# SWM261 register map
File version: 1.0
SWM261 Microcontroller registers
CPU: CM0 r1p0, little endian, 2 interrupt priority bits
Registers are 32-bit, read-write, no defined reset value unless marked. A register's access mark holds for its fields unless they carry their own. Offsets are from the block's base; lines under a group give offsets from that group; [hi:lo] are bit positions; {n}, {i} and the like mark numbered series; 'fields as' and 'values as' point back to an identical list; <NAME> marks a mode.

## Memory map
0x40000000 SYS size 0x45854 — Registers group
0x40000800 DMA size 0x50 — Registers group
0x40001800 QSPI0 size 0x44 — Registers group
0x40002800 CRC size 0x10 — Registers group
0x40003000 DIV size 0x28 — Registers group
0x40003800 GPIOA size 0x80 — Registers group
0x40004000 GPIOB size 0x80
0x40004800 GPIOC size 0x80
0x40005000 MPU size 0x18 — Registers group
0x40040000 UART0 size 0x20 — Registers group
0x40040800 UART1 size 0x20
0x40041000 QEI size 0x34 — Registers group
0x40041800 SPI0 size 0x14 — Registers group
0x40042000 I2C0 size 0x38 — Registers group
0x40042800 CAN0 size 0x3C0 — Registers group
0x40043000 PWM0 size 0x80 — Registers group
0x40043080 PWM1 size 0x80
0x40043400 PWMG size 0x2C — Registers group
0x40043800 TIMR0 size 0x34 — Registers group
0x40043840 TIMR1 size 0x34
0x40043880 TIMR2 size 0x34
0x40043C00 TIMRG size 0x44 — Registers group
0x40044000 BTIMR0 size 0x34
0x40044040 BTIMR1 size 0x34
0x40044080 BTIMR2 size 0x34
0x400440C0 BTIMR3 size 0x34
0x40044400 BTIMRG size 0x44
0x40044800 ADC0 size 0x204 — Registers group
0x40044900 ADC1 size 0x204
0x40045000 FMC size 0x2C — Registers group
0x40046000 PORTA size 0x404 — Registers group
0x40046010 PORTB size 0x404
0x40046020 PORTC size 0x404
0x40046800 WDT size 0x14 — Registers group
0x40047000 USART0 size 0x60 — Registers group

## SYS — Registers group
Base 0x40000000
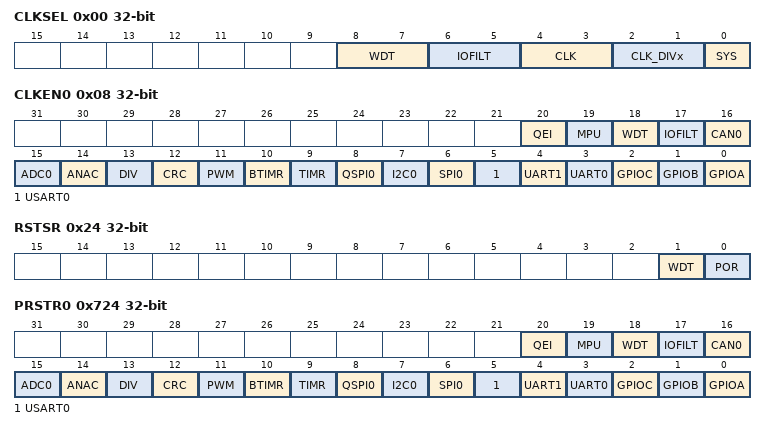
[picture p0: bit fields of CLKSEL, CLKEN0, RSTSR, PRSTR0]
0x00 CLKSEL
  [8:7] WDT, [6:5] IOFILT, [4:3] CLK, [2:1] CLK_DIVx, [0] SYS
0x04 CLKDIVx_ON
0x08 CLKEN0
  [20] QEI, [19] MPU, [18] WDT, [17] IOFILT, [16] CAN0, [15] ADC0, [14] ANAC, [13] DIV, [12] CRC, [11] PWM, [10] BTIMR, [9] TIMR, [8] QSPI0, [7] I2C0, [6] SPI0, [5] USART0, [4] UART1, [3] UART0, [2] GPIOC, [1] GPIOB, [0] GPIOA
0x10 SLEEP
  [0] SLEEP
0x24 RSTSR
  [1] WDT, [0] POR
{0x80+4i} CHIPID[{i}] (i=0..3) ro
{0x90+4i} BACKUP[{i}] (i=0..3)
0x100 PAWKEN
0x104 PBWKEN
0x108 PCWKEN
0x130 PAWKSR
0x134 PBWKSR
0x138 PCWKSR
0x400 IOFILT0
0x404 IOFILT1
0x720 PRSTEN
0x724 PRSTR0
  fields as CLKEN0
0x45800 PMUCR
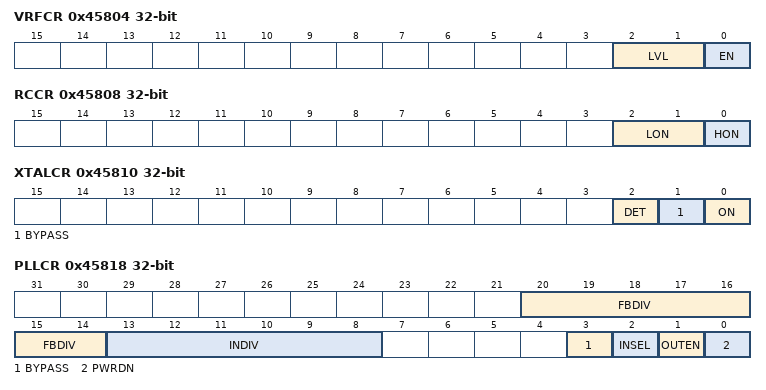
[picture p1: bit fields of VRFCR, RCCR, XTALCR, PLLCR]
0x45804 VRFCR
  [2:1] LVL, [0] EN
0x45808 RCCR
  [2:1] LON, [0] HON
0x45810 XTALCR
  [2] DET, [1] BYPASS, [0] ON
0x45814 XTALSR
  [0] STOP
0x45818 PLLCR
  [20:14] FBDIV, [13:8] INDIV, [3] BYPASS, [2] INSEL, [1] OUTEN, [0] PWRDN
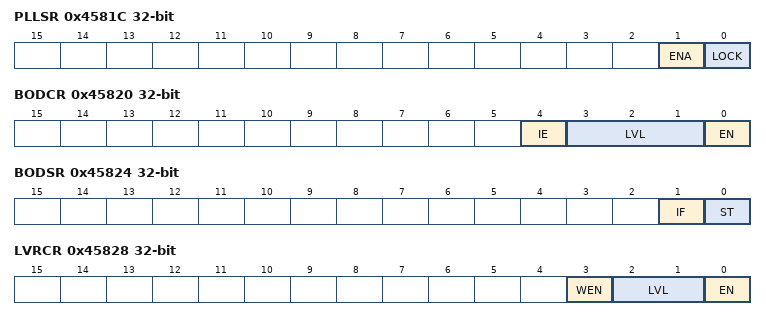
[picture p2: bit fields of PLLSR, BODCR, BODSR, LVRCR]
0x4581C PLLSR
  [1] ENA, [0] LOCK
0x45820 BODCR
  [4] IE, [3:1] LVL, [0] EN
0x45824 BODSR
  [1] IF, [0] ST
0x45828 LVRCR
  [3] WEN, [2:1] LVL, [0] EN
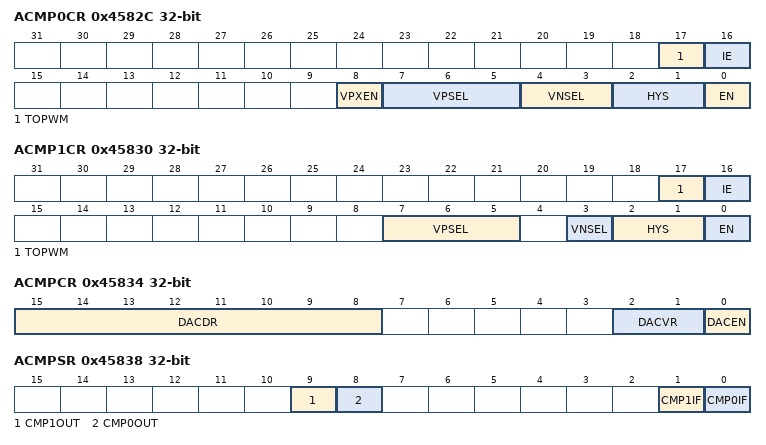
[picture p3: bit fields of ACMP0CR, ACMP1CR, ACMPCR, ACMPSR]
0x4582C ACMP0CR
  [17] TOPWM, [16] IE, [8] VPXEN, [7:5] VPSEL, [4:3] VNSEL, [2:1] HYS, [0] EN
0x45830 ACMP1CR
  [17] TOPWM, [16] IE, [7:5] VPSEL, [3] VNSEL, [2:1] HYS, [0] EN
0x45834 ACMPCR
  [15:8] DACDR, [2:1] DACVR, [0] DACEN
0x45838 ACMPSR
  [9] CMP1OUT, [8] CMP0OUT, [1] CMP1IF, [0] CMP0IF
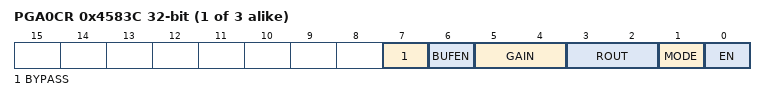
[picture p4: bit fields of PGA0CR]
{0x4583C+4i} PGA{i}CR (i=0..2)
  [7] BYPASS, [6] BUFEN, [5:4] GAIN, [3:2] ROUT, [1] MODE, [0] EN
0x45848 PGAREF
  [1:0] REFSEL
0x4584C TEMPCR
  [1:0] EN
0x45850 ADCREF
  [0] REFSEL

## PORTA — Registers group
Base 0x40046000
Same registers: PORTB 0x40046010, PORTC 0x40046020
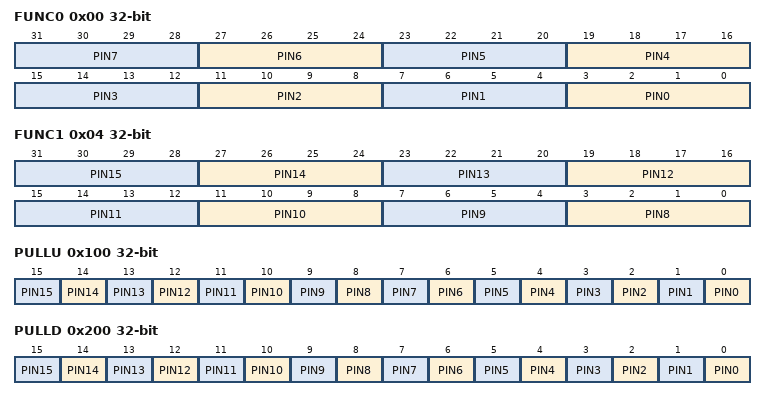
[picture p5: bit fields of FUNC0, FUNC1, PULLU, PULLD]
0x00 FUNC0
  [4n+3:4n] PIN{n} (n=0..7)
0x04 FUNC1
  [4n-29:4n-32] PIN{n} (n=8..15)
0x100 PULLU
  [n] PIN{n} (n=0..15)
0x200 PULLD
  [n] PIN{n} (n=0..15)
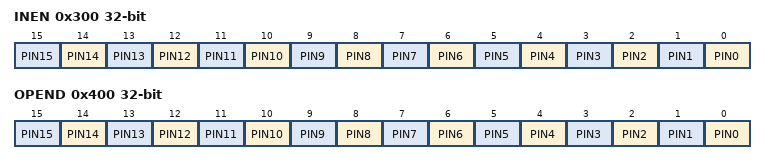
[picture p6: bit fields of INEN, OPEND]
0x300 INEN
  [n] PIN{n} (n=0..15)
0x400 OPEND
  [n] PIN{n} (n=0..15)

## GPIOA — Registers group
Base 0x40003800
Same registers: GPIOB 0x40004000, GPIOC 0x40004800
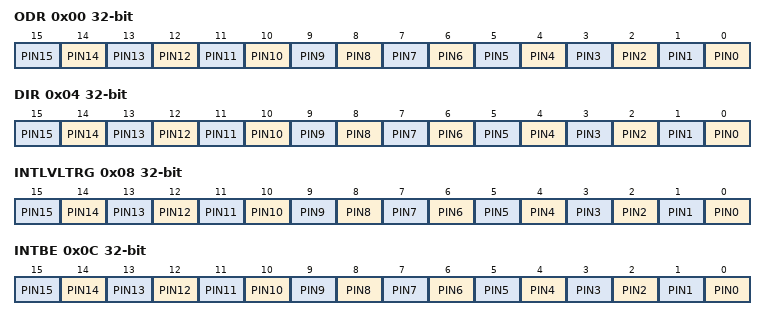
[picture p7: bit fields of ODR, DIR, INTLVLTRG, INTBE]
0x00 ODR
  [n] PIN{n} (n=0..15)
0x04 DIR
  [n] PIN{n} (n=0..15)
0x08 INTLVLTRG
  [n] PIN{n} (n=0..15)
0x0C INTBE
  [n] PIN{n} (n=0..15)
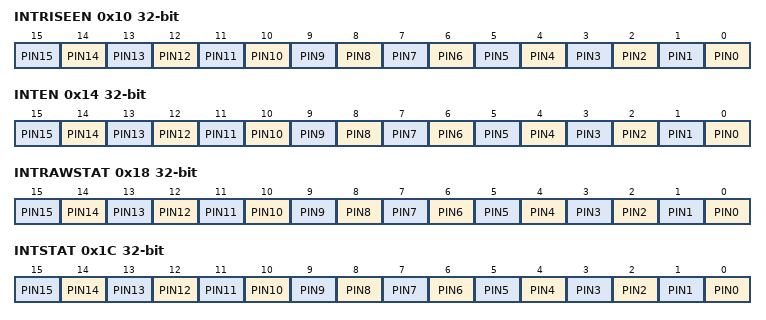
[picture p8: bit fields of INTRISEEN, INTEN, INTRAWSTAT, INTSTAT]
0x10 INTRISEEN
  [n] PIN{n} (n=0..15)
0x14 INTEN
  [n] PIN{n} (n=0..15)
0x18 INTRAWSTAT ro
  [n] PIN{n} (n=0..15)
0x1C INTSTAT ro
  [n] PIN{n} (n=0..15)
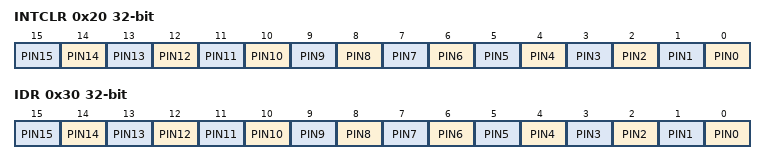
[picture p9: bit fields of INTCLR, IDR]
0x20 INTCLR wo
  [n] PIN{n} (n=0..15)
0x30 IDR ro
  [n] PIN{n} (n=0..15)
{0x40+4i} DATAPIN{i} (i=0..15)
